# SF32LB56x register map
File version: 1.0
CPU: CM33 r0p1, little endian, MPU, FPU, 3 interrupt priority bits
Registers are 32-bit, read-write, reset 0x0 unless marked. A register's access mark holds for its fields unless they carry their own. Offsets are from the block's base; [hi:lo] are bit positions; {n}, {i} and the like mark numbered series.

## LPSYS_AON
Base 0x50040000
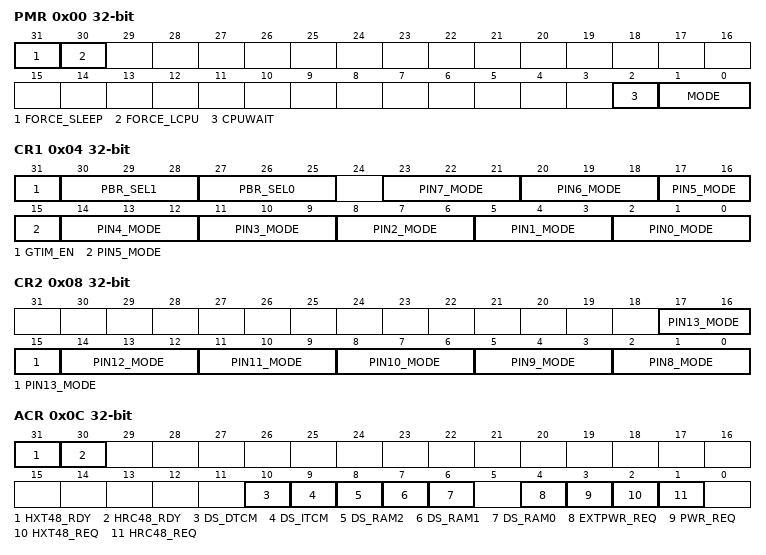
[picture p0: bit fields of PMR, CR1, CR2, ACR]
0x00 PMR — Power Mode Register
  [31] FORCE_SLEEP — Set 1 to force enter low power mode. Will be cleared automatically
  [30] FORCE_LCPU — 0: SWD connected to HCPU 1: SWD connected to LCPU
  [2] CPUWAIT — Stall CPU out of reset. Should be cleared before LCPU run
  [1:0] MODE — Power Mode: 2'h0 - active; 2'h1 - light sleep; 2'h2 - deep sleep; 2'h3 - standby
0x04 CR1 — Control Register 1
  [31] GTIM_EN — Enable global timer
  [30:28] PBR_SEL1 — for debug only
  [27:25] PBR_SEL0 — for debug only
  [23:21] PIN7_MODE — mode for wakeup PIN7 (PA52)
  [20:18] PIN6_MODE — mode for wakeup PIN6 (PA51)
  [17:15] PIN5_MODE — mode for wakeup PIN5 (PA50)
  [3n+2:3n] PIN{n}_MODE (n=1..4) — mode for wakeup PIN{n} (PB{n+32})
  [2:0] PIN0_MODE — mode for wakeup PIN0 (PB32) 0 - high level, 1 - low level, 2 - pos edge, 3 - neg edge, 4/5/6/7: pos or neg edge
0x08 CR2 — Control Register 2
  [3n-22:3n-24] PIN{n}_MODE (n=10..13) — mode for wakeup PIN{n} (PBR{n-10})
  [5:3] PIN9_MODE — mode for wakeup PIN9 (PA54)
  [2:0] PIN8_MODE — mode for wakeup PIN8 (PA53) 0 - high level, 1 - low level, 2 - pos edge, 3 - neg edge, 4/5/6/7: pos or neg edge
0x0C ACR — Active Mode Control register
  [31] HXT48_RDY — Indicate hxt48 is ready
  [30] HRC48_RDY — Indicate hrc48 is ready
  [10] DS_DTCM — for debug only
  [9] DS_ITCM — for debug only
  [8] DS_RAM2 — for debug only
  [7] DS_RAM1 — for debug only
  [6] DS_RAM0 — for debug only
  [4] EXTPWR_REQ — Request power for HPSYS during Active mode
  [3] PWR_REQ — Request power for LPSYS during Active mode
  [2] HXT48_REQ — Request hxt48 in active mode
  [1] HRC48_REQ — Request hrc48 in active mode
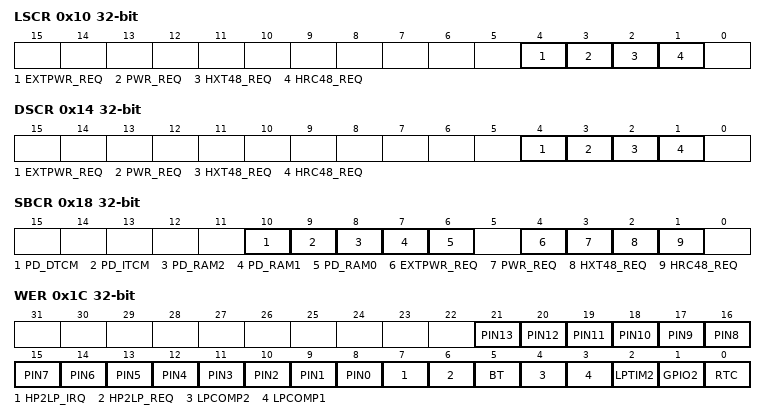
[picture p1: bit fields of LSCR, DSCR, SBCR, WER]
0x10 LSCR — Light Sleep Ctrl Register
  [4] EXTPWR_REQ — Request power for HPSYS during Light Sleep mode
  [3] PWR_REQ — Request power for LPSYS during Light Sleep mode
  [2] HXT48_REQ — Request hxt48 in Light Sleep mode
  [1] HRC48_REQ — Request hrc48 in Light Sleep mode
0x14 DSCR — Deep Sleep Ctrl Register
  [4] EXTPWR_REQ — Request power for HPSYS during Deep Sleep mode
  [3] PWR_REQ — Request power for LPSYS during Deep Sleep mode
  [2] HXT48_REQ — Request hxt48 in Deep Sleep mode
  [1] HRC48_REQ — Request hrc48 in Deep Sleep mode
0x18 SBCR — Standby Mode Ctrl Register
  [10] PD_DTCM — for debug only
  [9] PD_ITCM — for debug only
  [8] PD_RAM2 — for debug only
  [7] PD_RAM1 — for debug only
  [6] PD_RAM0 — for debug only
  [4] EXTPWR_REQ — Request power for HPSYS during Standby mode
  [3] PWR_REQ — Request power for LPSYS during Standby mode
  [2] HXT48_REQ — Request hxt48 in Standby mode
  [1] HRC48_REQ — Request hrc48 in Standby mode
0x1C WER — Wakeup Enable register
  [n+8] PIN{n} (n=10..13) — Set 1 to enable PBR{n-10} as wakeup source
  [n+8] PIN{n} (n=5..9) — Set 1 to enable PA{n+45} as wakeup source
  [n+8] PIN{n} (n=0..4) — Set 1 to enable PB{n+32} as wakeup source
  [7] HP2LP_IRQ — Set 1 to enable MAILBOX1 as wakeup source
  [6] HP2LP_REQ — Set 1 to enable HPSYS request as wakeup source
  [5] BT — Set 1 to enable BT as wakeup source
  [4] LPCOMP2 — Set 1 to enable LPCOMP2 as wakeup source
  [3] LPCOMP1 — Set 1 to enable LPCOMP1 as wakeup source
  [2] LPTIM2 — Set 1 to enable LPTIM2 as wakeup source
  [1] GPIO2 — Set 1 to enable IO(PB) as wakeup source
  [0] RTC — Set 1 to enable RTC as wakeup source
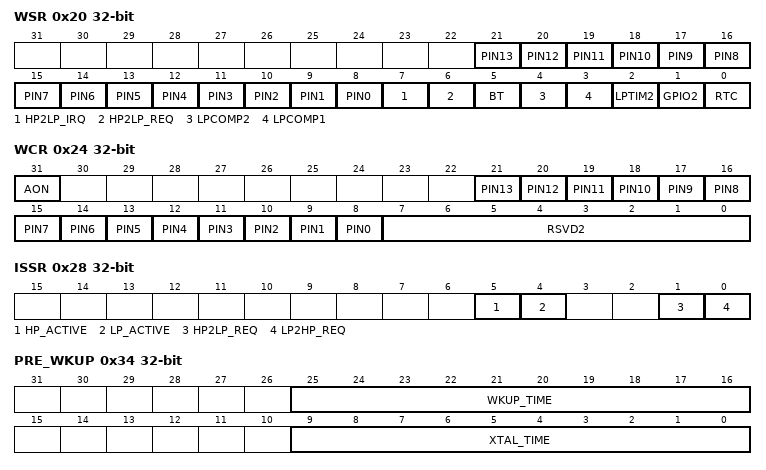
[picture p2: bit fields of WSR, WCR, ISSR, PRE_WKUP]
0x20 WSR — Wakeup Status register
  [n+8] PIN{n} (n=10..13) — Indicates the wakeup status from PBR{n-10} request. Note: the status is masked by WER
  [n+8] PIN{n} (n=5..9) — Indicates the wakeup status from PA{n+45} request. Note: the status is masked by WER
  [n+8] PIN{n} (n=0..4) — Indicates the wakeup status from PB{n+32} request. Note: the status is masked by WER
  [7] HP2LP_IRQ — Indicates the wakeup status from MAILBOX1. Note: the status is masked by WER
  [6] HP2LP_REQ — Indicates the wakeup status from HPSYS request. Note: the status is masked by WER
  [5] BT — Indicates the wakeup status from BT. Note: the status is masked by WER
  [4] LPCOMP2 — Indicates the wakeup status from LPCOMP2. Note: the status is masked by WER
  [3] LPCOMP1 — Indicates the wakeup status from LPCOMP1. Note: the status is masked by WER
  [2] LPTIM2 — Indicates the wakeup status from LPTIM2. Note: the status is masked by WER
  [1] GPIO2 — Indicates the wakeup status from IO(PB). Note: the status is masked by WER
  [0] RTC — Indicates the wakeup status from RTC. Note: the status is masked by WER
0x24 WCR — Wakeup Clear register
  [31] AON — Write 1 to clear the AON wakeup IRQ status
  [n+8] PIN{n} (n=10..13) — Write 1 to clear PBR{n-10} wakeup source. Only valid if PIN wakeup is configured as edge trigger
  [n+8] PIN{n} (n=5..9) — Write 1 to clear PA{n+45} wakeup source. Only valid if PIN wakeup is configured as edge trigger
  [n+8] PIN{n} (n=0..4) — Write 1 to clear PB{n+32} wakeup source. Only valid if PIN wakeup is configured as edge trigger
  [7:0] RSVD2 — Note: for RTC/GPIO/LPTIM/LPCOMP/BT, clear the wakeup status directly in the corresponding module
0x28 ISSR — Inter System Status Register
  [5] HP_ACTIVE — read 1 indicates HPSYS is active
  [4] LP_ACTIVE — write 1 to indicates LPSYS is active
  [1] HP2LP_REQ — indicate HPSYS request exists
  [0] LP2HP_REQ — write 1 to request HPSYS to stay in active mode
0x2C TARGET — BT sleep time target
  [27:0] SLEEP_TARGET — bt sleep time target in cycles of clk_lp
0x30 ACTUAL — BT actual sleep time
  [27:0] SLEEP_CNT — bt actual sleep time in cycles of clk_lp. If not woken up by software or external interrupt, sleep_cnt counts up every clk_lp cycle, until reaches sleep_target
0x34 PRE_WKUP — time before bt awake
  [25:16] WKUP_TIME — cycles of clk_lp for LPSYS ready before bt awake.
  [9:0] XTAL_TIME — cycles of clk_lp for hxt48 ready before bt awake.
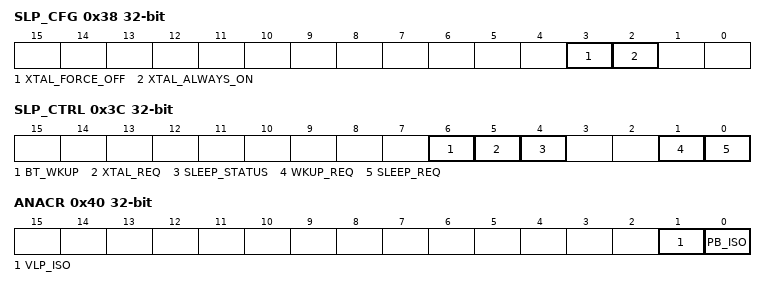
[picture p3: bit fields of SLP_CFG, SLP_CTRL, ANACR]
0x38 SLP_CFG — BT sleep configuration
  [3] XTAL_FORCE_OFF — for debug only
  [2] XTAL_ALWAYS_ON — for debug only
0x3C SLP_CTRL — BT sleep control
  [6] BT_WKUP — bt wakeup source. 1 means bt has not enter sleep or has enter wakeup procedure
  [5] XTAL_REQ — xtal request status. 1 means bt is requiring xtal.
  [4] SLEEP_STATUS — bt sleep status. 1 means bt is sleeping and sleep_cnt is counting up
  [1] WKUP_REQ — software request to wakeup bt. Will be cleared automatically
  [0] SLEEP_REQ — bt sleep request. Will be cleared automatically
0x40 ANACR — Analog Control Register
  [1] VLP_ISO — Set 1 to force off all LPSYS related analog modules
  [0] PB_ISO — Set 1 to force IO(PB) into retention mode
0x44 GTIMR — Global Timer Register
  [31:0] CNT — Global timer value
0x48 RESERVE0 — Reserved Register 0
  [31:0] DATA — for debug only
0x4C RESERVE1 — Reserved Register 1
  [31:0] DATA — for debug only
0x100 SPR — Stack Pointer Register
  [31:0] SP — LCPU stack pointer address
0x104 PCR — Pointer Counter Register
  [31:0] PC — LCPU PC pointer address
